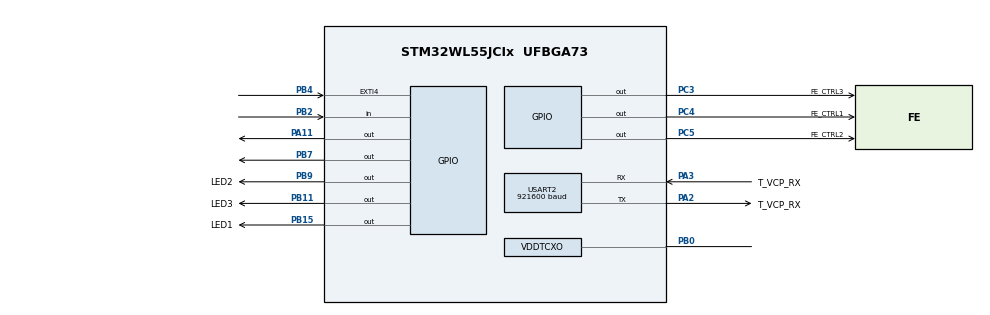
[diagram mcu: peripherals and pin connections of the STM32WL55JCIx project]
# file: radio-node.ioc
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IWDG.Prescaler=IWDG_PRESCALER_128
Mcu.Family=STM32WL
Mcu.Name=STM32WL55JCIx
Mcu.Package=UFBGA73
NVIC.EXTI4_IRQn=true\:0\:0\:false\:false\:true\:true\:true\:true
NVIC.PriorityGroup=NVIC_PRIORITYGROUP_4
NVIC.RTC_WKUP_IRQn=true\:0\:0\:false\:false\:true\:true\:true\:true
NVIC.SUBGHZ_Radio_IRQn=true\:0\:0\:false\:false\:true\:true\:true\:true
NVIC.USART2_IRQn=true\:0\:0\:false\:false\:true\:true\:true\:true
OSC_IN.Mode=HSE-TCXO
OSC_IN.Signal=RCC_OSC_IN
PA11.Signal=GPIO_Output
PA13.Mode=Serial_Wire
PA13.Signal=DEBUG_JTMS-SWDIO
PA14.Mode=Serial_Wire
PA14.Signal=DEBUG_JTCK-SWCLK
PA2.GPIO_Label=T_VCP_RX
PA2.Mode=Asynchronous
PA2.Signal=USART2_TX
PA3.GPIO_Label=T_VCP_RX
PA3.Mode=Asynchronous
PA3.Signal=USART2_RX
PB0-VDD_TCXO.Mode=HSE-TCXO
PB0-VDD_TCXO.Signal=VDDTCXO
PB11.GPIO_Label=LED3
PB11.GPIO_Speed=GPIO_SPEED_FREQ_HIGH
PB11.Signal=GPIO_Output
PB15.GPIO_Label=LED1
PB15.GPIO_Speed=GPIO_SPEED_FREQ_HIGH
PB15.Signal=GPIO_Output
PB2.GPIO_PuPd=GPIO_PULLDOWN
PB2.Signal=GPIO_Input
PB4.GPIO_PuPd=GPIO_PULLDOWN
PB4.Signal=GPXTI4
PB7.Signal=GPIO_Output
PB9.GPIO_FM9=__NULL
PB9.GPIO_Label=LED2
PB9.GPIO_Speed=GPIO_SPEED_FREQ_HIGH
PB9.Signal=GPIO_Output
PC14-OSC32_IN.Mode=LSE-External-Oscillator
PC14-OSC32_IN.Signal=RCC_OSC32_IN
PC15-OSC32_OUT.Mode=LSE-External-Oscillator
PC15-OSC32_OUT.Signal=RCC_OSC32_OUT
PC3.GPIO_Label=FE_CTRL3
PC3.GPIO_Speed=GPIO_SPEED_FREQ_VERY_HIGH
PC3.Signal=GPIO_Output
PC4.GPIO_Label=FE_CTRL1
PC4.GPIO_Speed=GPIO_SPEED_FREQ_VERY_HIGH
PC4.Signal=GPIO_Output
PC5.GPIO_Label=FE_CTRL2
PC5.GPIO_Speed=GPIO_SPEED_FREQ_VERY_HIGH
PC5.Signal=GPIO_Output
ProjectManager.HeapSize=0x200
ProjectManager.StackSize=0x400
ProjectManager.TargetToolchain=Makefile
RCC.AHBFreq_Value=48000000
RCC.APB1Freq_Value=48000000
RCC.APB1TimFreq_Value=48000000
RCC.APB2Freq_Value=48000000
RCC.APB2TimFreq_Value=48000000
RCC.APB3Freq_Value=48000000
RCC.CortexFreq_Value=48000000
RCC.HCLKFreq_Value=48000000
RCC.HSEPRES=2
RCC.HSE_VALUE=32000000
RCC.HSI_VALUE=16000000
RCC.LSE_VALUE=32768
RCC.MSIClockRange=RCC_MSIRANGE_11
RCC.PLLSourceVirtual=RCC_PLLSOURCE_HSI
RCC.SYSCLKFreq_VALUE=48000000
RCC.VCOOutputFreq_Value=128000000
RTC.WakeUpClock-WakeUp=RTC_WAKEUPCLOCK_RTCCLK_DIV2
RTC.WakeUpCounter-WakeUp=15
SUBGHZ.BaudratePrescaler=SUBGHZSPI_BAUDRATEPRESCALER_4
TIM2.AutoReloadPreload=TIM_AUTORELOAD_PRELOAD_ENABLE
TIM2.Period=100000000-1
TIM2.Prescaler=48-1
USART2.BaudRate=921600
USART2.VirtualMode-Asynchronous=VM_ASYNC
VP_IWDG_VS_IWDG.Mode=IWDG_Activate
VP_RTC_VS_RTC_Activate.Mode=RTC_Enabled
VP_RTC_VS_RTC_WakeUp_intern.Mode=WakeUp
VP_SUBGHZ_VS_SUBGHZ.Mode=SUBGHZ_Activate
VP_TIM2_VS_ClockSourceINT.Mode=Internal
board=NUCLEO-WL55JC1

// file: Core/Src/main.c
/* USER CODE BEGIN Header */
/**
  ******************************************************************************
  * @file           : main.c
  * @brief          : Main program body
  ******************************************************************************
  * @attention
  *
  * <h2><center>&copy; Copyright (c) 2021 STMicroelectronics.
  * All rights reserved.</center></h2>
  *
  * This software component is licensed by ST under BSD 3-Clause license,
  * the "License"; You may not use this file except in compliance with the
  * License. You may obtain a copy of the License at:
  *                        opensource.org/licenses/BSD-3-Clause
  *
  ******************************************************************************
  */
/* USER CODE END Header */
#include "main.h"
#include "iwdg.h"
#include "rtc.h"
#include "subghz.h"
#include "tim.h"
#include "usart.h"
#include "gpio.h"

/* USER CODE BEGIN Includes */
#include "LoRa.h"
/* USER CODE END Includes */

/* USER CODE BEGIN PV */
uint32_t RTCwakeUpTimer = 0;
/* USER CODE END PV */

void SystemClock_Config(void);

/* USER CODE BEGIN 0 */

void HAL_RTCEx_WakeUpTimerEventCallback(RTC_HandleTypeDef *hrtc)
{
  /* Prevent unused argument(s) compilation warning */
  UNUSED(hrtc);
  //HAL_GPIO_TogglePin(GPIOB, GPIO_PIN_7);
  RTCwakeUpTimer++;
}

/* USER CODE END 0 */

int main(void)
{

  /* MCU Configuration--------------------------------------------------------*/

  /* Reset of all peripherals, Initializes the Flash interface and the Systick. */
  HAL_Init();

  /* Configure the system clock */
  SystemClock_Config();

  /* Initialize all configured peripherals */
  MX_GPIO_Init();
  MX_SUBGHZ_Init();
  MX_USART2_UART_Init();
  MX_TIM2_Init();
  MX_RTC_Init();
  MX_IWDG_Init();
  /* USER CODE BEGIN 2 */
  radio_init();
  HAL_TIM_Base_Start(&htim2);

  //DBGMCU->APB1FZR1 |= DBGMCU_APB1FZR1_DBG_TIM2_STOP;

  (uint32_t)__HAL_TIM_SET_COUNTER(&htim2, 0);
  extern volatile uint8_t uart_byte;
  HAL_UART_Receive_IT(&huart2, &uart_byte, (1));
  /* USER CODE END 2 */

  /* Infinite loop */
  while (1)
  {

    /* USER CODE BEGIN 3 */
    HAL_IWDG_Refresh(&hiwdg);
    radio_configurations();
  }
  /* USER CODE END 3 */
}

void SystemClock_Config(void)
{
  RCC_OscInitTypeDef RCC_OscInitStruct = {0};
  RCC_ClkInitTypeDef RCC_ClkInitStruct = {0};

  /** Configure LSE Drive Capability
  */
  HAL_PWR_EnableBkUpAccess();
  __HAL_RCC_LSEDRIVE_CONFIG(RCC_LSEDRIVE_LOW);

  /** Configure the main internal regulator output voltage
  */
  __HAL_PWR_VOLTAGESCALING_CONFIG(PWR_REGULATOR_VOLTAGE_SCALE1);

  /** Initializes the CPU, AHB and APB buses clocks
  */
  RCC_OscInitStruct.OscillatorType = RCC_OSCILLATORTYPE_LSI|RCC_OSCILLATORTYPE_LSE
                              |RCC_OSCILLATORTYPE_MSI;
  RCC_OscInitStruct.LSEState = RCC_LSE_ON;
  RCC_OscInitStruct.MSIState = RCC_MSI_ON;
  RCC_OscInitStruct.MSICalibrationValue = RCC_MSICALIBRATION_DEFAULT;
  RCC_OscInitStruct.MSIClockRange = RCC_MSIRANGE_11;
  RCC_OscInitStruct.LSIDiv = RCC_LSI_DIV1;
  RCC_OscInitStruct.LSIState = RCC_LSI_ON;
  RCC_OscInitStruct.PLL.PLLState = RCC_PLL_NONE;
  if (HAL_RCC_OscConfig(&RCC_OscInitStruct) != HAL_OK)
  {
    Error_Handler();
  }

  /** Configure the SYSCLKSource, HCLK, PCLK1 and PCLK2 clocks dividers
  */
  RCC_ClkInitStruct.ClockType = RCC_CLOCKTYPE_HCLK3|RCC_CLOCKTYPE_HCLK
                              |RCC_CLOCKTYPE_SYSCLK|RCC_CLOCKTYPE_PCLK1
                              |RCC_CLOCKTYPE_PCLK2;
  RCC_ClkInitStruct.SYSCLKSource = RCC_SYSCLKSOURCE_MSI;
  RCC_ClkInitStruct.AHBCLKDivider = RCC_SYSCLK_DIV1;
  RCC_ClkInitStruct.APB1CLKDivider = RCC_HCLK_DIV1;
  RCC_ClkInitStruct.APB2CLKDivider = RCC_HCLK_DIV1;
  RCC_ClkInitStruct.AHBCLK3Divider = RCC_SYSCLK_DIV1;

  if (HAL_RCC_ClockConfig(&RCC_ClkInitStruct, FLASH_LATENCY_2) != HAL_OK)
  {
    Error_Handler();
  }
}

void Error_Handler(void)
{
  __disable_irq();
  while (1)
  {
  }
}
